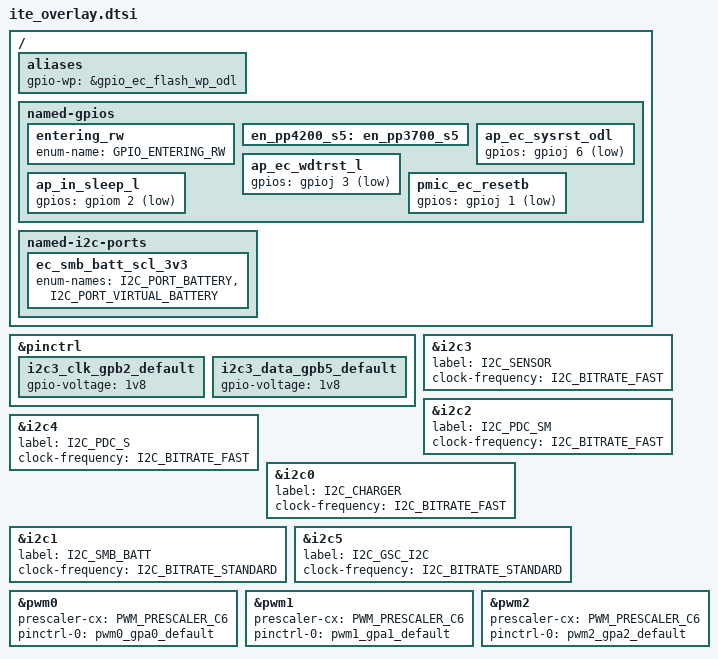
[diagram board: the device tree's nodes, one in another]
/* Copyright 2025 The ChromiumOS Authors
 * Use of this source code is governed by a BSD-style license that can be
 * found in the LICENSE file.
 *
 */

/ {
	aliases {
		gpio-wp = &gpio_ec_flash_wp_odl;
	};

	named-gpios {
		entering_rw {
			enum-name = "GPIO_ENTERING_RW";
		};
		en_pp4200_s5: en_pp3700_s5 {};
		ap_ec_sysrst_odl {
			gpios = <&gpioj 6 (GPIO_INPUT | GPIO_VOLTAGE_1P8 |
						GPIO_ACTIVE_LOW)>;
		};
		ap_ec_wdtrst_l {
			gpios = <&gpioj 3 (GPIO_INPUT | GPIO_VOLTAGE_1P8 |
						GPIO_ACTIVE_LOW)>;
		};
		ap_in_sleep_l {
			gpios = <&gpiom 2 (GPIO_INPUT | GPIO_VOLTAGE_1P8 |
						GPIO_ACTIVE_LOW)>;
		};
		pmic_ec_resetb {
			gpios = <&gpioj 1 (GPIO_INPUT | GPIO_VOLTAGE_1P8 |
					   GPIO_ACTIVE_LOW)>;
		};
	};

	named-i2c-ports {
		ec_smb_batt_scl_3v3 {
			enum-names = "I2C_PORT_BATTERY", "I2C_PORT_VIRTUAL_BATTERY";
		};
	};
};

&pinctrl {
	/* I2C property setting */
	i2c3_clk_gpb2_default: i2c3_clk_gpb2_default {
		gpio-voltage = "1v8";
	};
	i2c3_data_gpb5_default: i2c3_data_gpb5_default {
		gpio-voltage = "1v8";
	};
};

&i2c3 {
	label = "I2C_SENSOR";
	clock-frequency = <I2C_BITRATE_FAST>;
};

&i2c2 {
	label = "I2C_PDC_SM";
	clock-frequency = <I2C_BITRATE_FAST>;
};

&i2c4 {
	label = "I2C_PDC_S";
	clock-frequency = <I2C_BITRATE_FAST>;
};

&i2c0 {
	label = "I2C_CHARGER";
	clock-frequency = <I2C_BITRATE_FAST>;
};

&i2c1 {
	label = "I2C_SMB_BATT";
	clock-frequency = <I2C_BITRATE_STANDARD>;
};

&i2c5 {
	label = "I2C_GSC_I2C";
	clock-frequency = <I2C_BITRATE_STANDARD>;
};

/* LED1 */
&pwm0 {
	status = "okay";
	prescaler-cx = <PWM_PRESCALER_C6>;
	pinctrl-0 = <&pwm0_gpa0_default>;
	pinctrl-names = "default";
};

/* LED2 */
&pwm1 {
	status = "okay";
	prescaler-cx = <PWM_PRESCALER_C6>;
	pinctrl-0 = <&pwm1_gpa1_default>;
	pinctrl-names = "default";
};

/* LED3 */
&pwm2 {
	status = "okay";
	prescaler-cx = <PWM_PRESCALER_C6>;
	pinctrl-0 = <&pwm2_gpa2_default>;
	pinctrl-names = "default";
};
